AUTOSAR XML (schema 4.0)
package /S01UCON/If
  sender receiver interface CellLink
    data val
  sender receiver interface DbusCmd
    data val
  sender receiver interface CanFrame
    data val
package /S01UCON/Swc
  application sw component type Telematics
    provide port cellToHuOut: provided-interface=CellLink
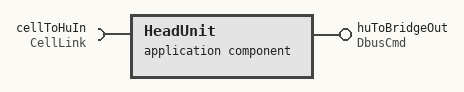
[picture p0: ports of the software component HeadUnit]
  application sw component type HeadUnit
    provide port huToBridgeOut: provided-interface=DbusCmd
    require port cellToHuIn: required-interface=CellLink
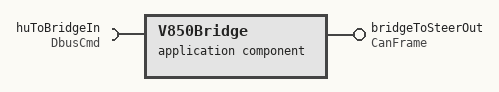
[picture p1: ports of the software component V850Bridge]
  application sw component type V850Bridge
    provide port bridgeToSteerOut: provided-interface=CanFrame
    require port huToBridgeIn: required-interface=DbusCmd
  application sw component type SteeringCtrl
    require port bridgeToSteerIn: required-interface=CanFrame
  composition sw component type Root
    4 x component:
      tel: type=Telematics
      ivi: type=HeadUnit
      bridge: type=V850Bridge
      steer: type=SteeringCtrl
    connect tel.cellToHuOut -> ivi.cellToHuIn
    connect ivi.huToBridgeOut -> bridge.huToBridgeIn
    connect bridge.bridgeToSteerOut -> steer.bridgeToSteerIn
package /S01UCON/Comm
  pdu huToBridgeIPdu
    signal huToBridgeISig: system signal huToBridgeSSig
  pdu bridgeToSteerIPdu
    signal bridgeToSteerISig: system signal bridgeToSteerSSig
package /S01UCON/Topology
  ecu instance ChassisEcu
  ecu instance GatewayEcu
  ecu instance TelematicsEcu
  system Veh
    root-software-compositions:
      root sw composition prototype Root: software-composition=Root
    system mapping Map
      data-mappings:
        data-element=Root.huToBridgeOut.val, system-signal=huToBridgeSSig
        data-element=Root.bridgeToSteerOut.val, system-signal=bridgeToSteerSSig
      sw-mappings:
        swc to ecu mapping ToChassisEcu: component=steer, ecu-instance=ChassisEcu
        swc to ecu mapping ToGatewayEcu: component=bridge, ecu-instance=GatewayEcu
        swc to ecu mapping ToTelematicsEcu: component=[tel, ivi], ecu-instance=TelematicsEcu
